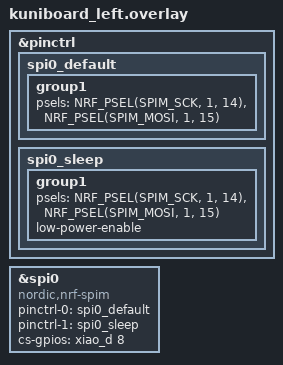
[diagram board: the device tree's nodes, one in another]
/*
 * Copyright (c) 2024 ZMK
 *
 * SPDX-License-Identifier: MIT
 */

#include "kuniboard.dtsi"

&pinctrl {
	spi0_default: spi0_default {
		group1 {
			psels = <NRF_PSEL(SPIM_SCK, 1, 14)>,
				<NRF_PSEL(SPIM_MOSI, 1, 15)>;
		};
	};
	spi0_sleep: spi0_sleep {
		group1 {
			psels = <NRF_PSEL(SPIM_SCK, 1, 14)>,
				<NRF_PSEL(SPIM_MOSI, 1, 15)>;
			low-power-enable;
		};
	};	
};
display_spi: &spi0 {
	compatible = "nordic,nrf-spim";
	pinctrl-0 = <&spi0_default>;
	pinctrl-1 = <&spi0_sleep>;
	pinctrl-names = "default", "sleep";
	cs-gpios = <&xiao_d 8 GPIO_ACTIVE_HIGH>;
};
